# G32R501 register map
Vendor: Geehy Semiconductor Co., Ltd.; Series: G32R5; File version: 1.0
CPU: CM55 r0p1, little endian, MPU, FPU, double-precision FPU, DSP, VTOR, 4 interrupt priority bits
Registers are 32-bit, read-write, reset 0x0 unless marked. A register's access mark holds for its fields unless they carry their own. Offsets are from the block's base; [hi:lo] are bit positions; {n}, {i} and the like mark numbered series.

## WDT — Watchdog Timer
Base 0x50026400
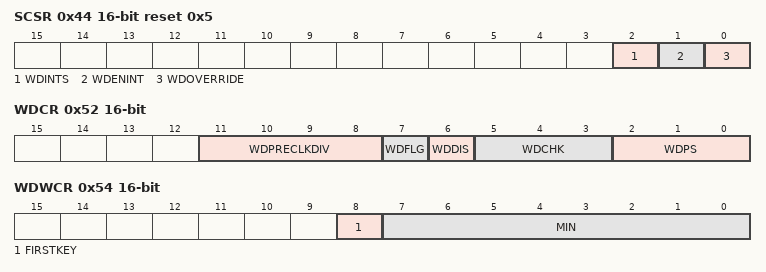
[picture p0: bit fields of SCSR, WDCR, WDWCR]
0x44 SCSR 16-bit access per field reset 0x5 — System Control & Status Register
  [2] WDINTS ro — Watchdog Interrupt Status
  [1] WDENINT rw — Watchdog Interrupt Enable/Reset Disable
  [0] WDOVERRIDE rw — Watchdog Enable Lock
0x46 WDCNTR 16-bit ro — Watchdog Counter Register
  [7:0] WDCNTR — Watchdog Counter
0x4A WDKEY 16-bit — Watchdog Reset Key Register
  [7:0] WDKEY — Watchdog Counter Reset
0x52 WDCR 16-bit — Watchdog Control Register
  [11:8] WDPRECLKDIV — Watchdog Clock Pre-divider
  [7] WDFLG — Watchdog reset status flag bit
  [6] WDDIS — Watchdog Disable
  [5:3] WDCHK — Watchdog Check Bits
  [2:0] WDPS — Watchdog Clock Prescaler
0x54 WDWCR 16-bit access per field — Watchdog Windowed Control Register
  [8] FIRSTKEY ro — First valid WDKEY detected
  [7:0] MIN rw — Watchdog Window Threshold

## SPEC — SPEC_REGS
Base 0x50020000
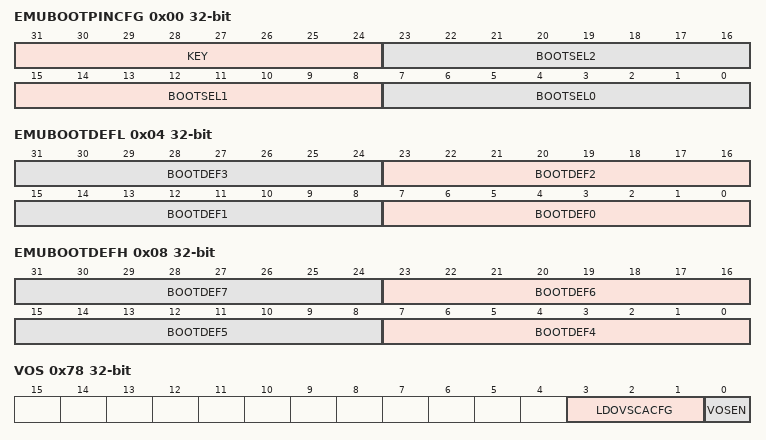
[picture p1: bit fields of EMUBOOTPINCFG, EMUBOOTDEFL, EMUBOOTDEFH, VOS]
0x00 EMUBOOTPINCFG — Emulation Boot pin configuration register
  [31:24] KEY — Key Word
  [23:16] BOOTSEL2 — Boot Mode Select Pin 2
  [15:8] BOOTSEL1 — Boot Mode Select Pin 1
  [7:0] BOOTSEL0 — Boot Mode Select Pin 0
0x04 EMUBOOTDEFL — Emulation Boot definition low register
  [8n+7:8n] BOOTDEF{n} (n=0..3) — BOOT_DEF{n} Mode/Options
0x08 EMUBOOTDEFH — Emulation Boot definition high register
  [8n-25:8n-32] BOOTDEF{n} (n=4..7) — BOOT_DEF{n} Mode/Options
0x54 BOOTADDR1 — BOOT address register 1
  [31:0] BOOTADDR1 — CPU1 boot address
0x58 BOOTCTRL — BOOT control register
  [1] BOOTCTRL1 — Allows CPU1 to boot
0x64 CFGSMSSEL reset 0x8 — CFGSMS static configuration selection register
  [3:0] CFGSMSSEL — CFGSMS Static configuration Select
0x74 APBCLKDIVCFG reset 0x3 — APB clock divider control register
  [4:0] APBCLKDIVCFG — APB clock divide configure
0x78 VOS — LDO voltage scaling control register
  [3:1] LDOVSCACFG — LDO voltage scaling configure
  [0] VOSEN — VOS Enable

## DMA_CHSEL — DMA Channel Trigger Source Select
Base 0x50020400
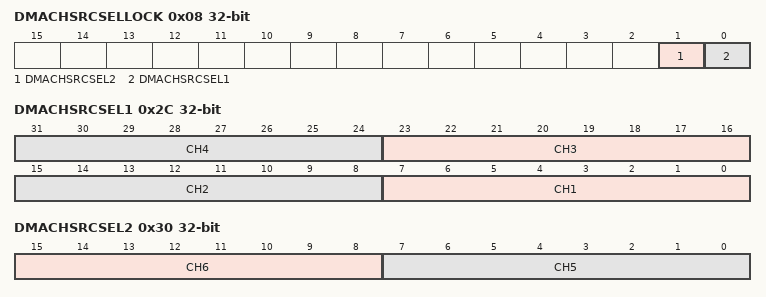
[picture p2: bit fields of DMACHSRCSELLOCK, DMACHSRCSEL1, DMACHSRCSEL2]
0x08 DMACHSRCSELLOCK — DMA Channel Triger Source Select Lock Register
  [1] DMACHSRCSEL2 — DMACHSRCSEL2 Register Lock bit
  [0] DMACHSRCSEL1 — DMACHSRCSEL1 Register Lock bit
0x2C DMACHSRCSEL1 — DMA Channel Trigger Source Select Register-1
  [8n-1:8n-8] CH{n} (n=1..4) — Selects the Trigger and Sync Source CH{n} of DMA
0x30 DMACHSRCSEL2 — DMA Channel Trigger Source Select Register-2
  [15:8] CH6 — Selects the Trigger and Sync Source CH6 of DMA
  [7:0] CH5 — Selects the Trigger and Sync Source CH5 of DMA

## DEV — DEV_REGS
Base 0x50020500
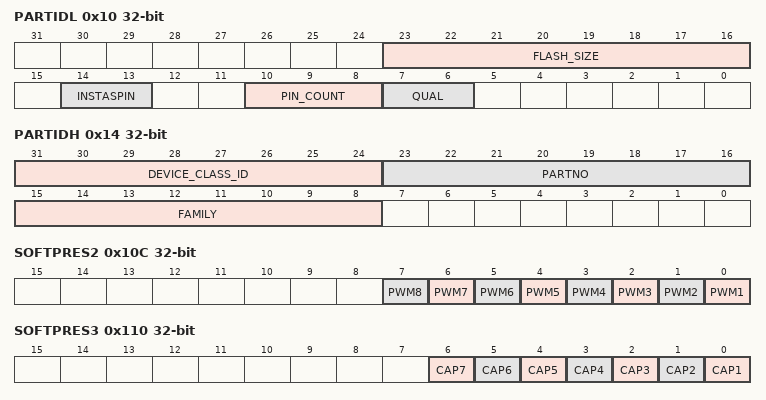
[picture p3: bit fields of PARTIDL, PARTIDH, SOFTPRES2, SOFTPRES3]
0x10 PARTIDL ro — Lower 32-bit of Device PART Identification Numble
  [23:16] FLASH_SIZE — Flash size in KB
  [14:13] INSTASPIN — Instaspin feature set
  [10:8] PIN_COUNT — Device Pin Count
  [7:6] QUAL — Qualification Status
0x14 PARTIDH ro — Upper 32-bit of Device PART Identification Numble
  [31:24] DEVICE_CLASS_ID
  [23:16] PARTNO — Device part number
  [15:8] FAMILY — Device family
0x18 REVID ro — Device Revision Number
  [15:0] REVID — Device Revision
0x104 SOFTPRES0 — Peripheral Software Reset register
  [0] CPU1 — CPU1 reset Configuration
0x10C SOFTPRES2 — Peripheral Software Reset register
  [n-1] PWM{n} (n=1..8) — PWM{n} reset Configuration
0x110 SOFTPRES3 — Peripheral Software Reset register
  [n-1] CAP{n} (n=1..7) — CAP{n} reset Configuration
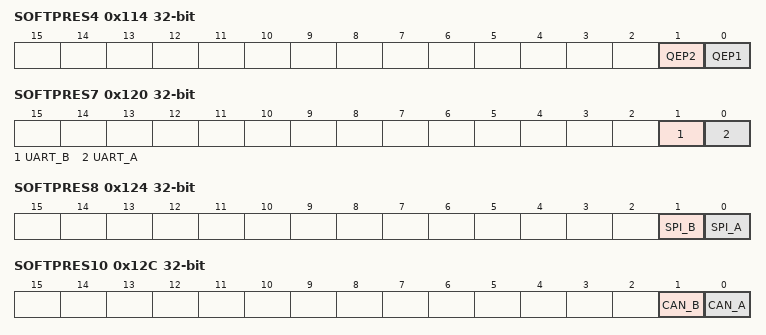
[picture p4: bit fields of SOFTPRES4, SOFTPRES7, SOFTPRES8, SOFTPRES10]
0x114 SOFTPRES4 — Peripheral Software Reset register
  [1] QEP2 — QEP2 reset Configuration
  [0] QEP1 — QEP1 reset Configuration
0x11C SOFTPRES6 — Peripheral Software Reset register
  [0] SD1 — SD1 reset Configuration
0x120 SOFTPRES7 — Peripheral Software Reset register
  [1] UART_B — UART_B reset Configuration
  [0] UART_A — UART_A reset Configuration
0x124 SOFTPRES8 — Peripheral Software Reset register
  [1] SPI_B — SPI_B reset Configuration
  [0] SPI_A — SPI_A reset Configuration
0x128 SOFTPRES9 — Peripheral Software Reset register
  [0] I2C_A — I2C_A reset Configuration
0x12C SOFTPRES10 — Peripheral Software Reset register
  [1] CAN_B — CAN_B reset Configuration
  [0] CAN_A — CAN_A reset Configuration
0x130 SOFTPRES11 — Peripheral Software Reset register
  [0] QSPI — QSPI reset Configuration
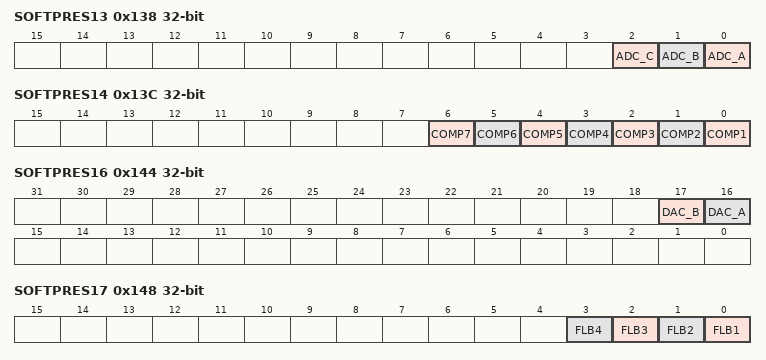
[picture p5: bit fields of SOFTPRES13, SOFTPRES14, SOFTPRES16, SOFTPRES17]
0x138 SOFTPRES13 — Peripheral Software Reset register
  [2] ADC_C — ADC_C reset Configuration
  [1] ADC_B — ADC_B reset Configuration
  [0] ADC_A — ADC_A reset Configuration
0x13C SOFTPRES14 — Peripheral Software Reset register
  [n-1] COMP{n} (n=1..7) — COMP{n} reset Configuration
0x144 SOFTPRES16 — Peripheral Software Reset register
  [17] DAC_B — DAC_B reset Configuration
  [16] DAC_A — DAC_A reset Configuration
0x148 SOFTPRES17 — Peripheral Software Reset register
  [n-1] FLB{n} (n=1..4) — FLB{n} reset Configuration
0x150 SOFTPRES19 — Peripheral Software Reset register
  [0] LIN_A — LIN_A reset Configuration
0x154 SOFTPRES20 — Peripheral Software Reset register
  [0] PMBUS_A — PMBUS_A reset Configuration
0x25C PACKSEL ro — Chip Footprint Select
  [3:0] PACKSEL — Chip Package Select
